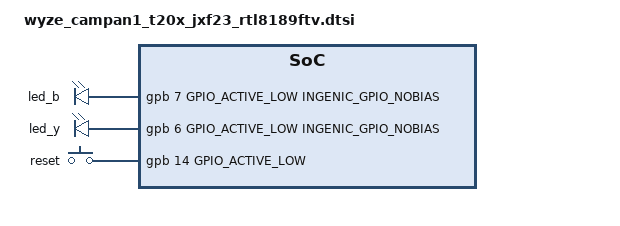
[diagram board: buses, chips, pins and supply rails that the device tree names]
// Wyze Cam Pan v1 (T20X, JXF23, RTL8189FTV) per-board GPIO definitions.
// Injected into the kernel 4.4+ device tree; ignored on 3.10.

#include <dt-bindings/gpio/gpio.h>
#include <dt-bindings/input/input.h>
#include <dt-bindings/pinctrl/ingenic-pinctrl.h>

/ {
	gpio-leds {
		compatible = "gpio-leds";

		led_b {
			label = "led_b";
			gpios = <&gpb 7 GPIO_ACTIVE_LOW INGENIC_GPIO_NOBIAS>;
			default-state = "off";
		};

		led_y {
			label = "led_y";
			gpios = <&gpb 6 GPIO_ACTIVE_LOW INGENIC_GPIO_NOBIAS>;
			default-state = "off";
		};
	};
};

/* Card detect; the family tree carries the reference pin. */
&msc0 {
	ingenic,cd-gpios = <&gpb 27 GPIO_ACTIVE_LOW INGENIC_GPIO_PULLUP>;
};

/ {
	gpio-keys {
		compatible = "gpio-keys";
		label = "gpio-keys";

		reset {
			label = "reset";
			linux,code = <KEY_ENTER>;
			gpios = <&gpb 14 GPIO_ACTIVE_LOW INGENIC_GPIO_PULLUP>;
		};
	};
};
